# HDSC_HC32M120F6TB register map
Vendor: HDSC Co.,Ltd.; Series: ARMCM0P; File version: 1.0
CPU: CM0P r0p1, little endian, no MPU, no FPU, 4 interrupt priority bits
Registers are 32-bit, read-write, reset 0x0 unless marked. A register's access mark holds for its fields unless they carry their own. Offsets are from the block's base; [hi:lo] are bit positions; {n}, {i} and the like mark numbered series; 'fields as' and 'values as' point back to an identical list.

## CRC
Base 0x40015400
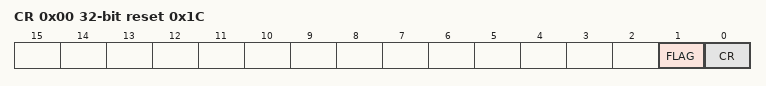
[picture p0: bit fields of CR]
0x00 CR reset 0x1C
  [1] FLAG, [0] CR
0x04 RESLT reset 0x7800
{0x80+4i} DAT{i} (i=0..31)

## CTC
Base 0x40000000
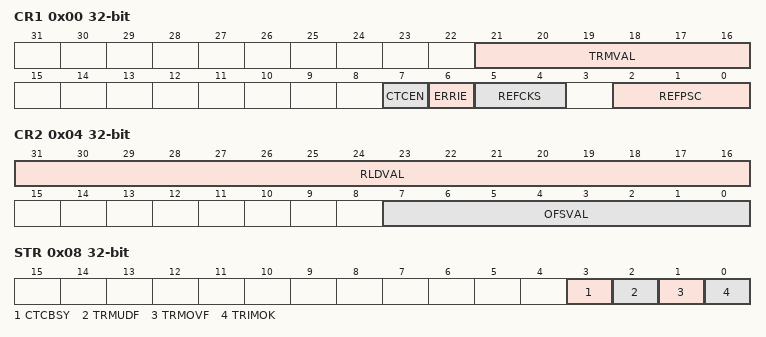
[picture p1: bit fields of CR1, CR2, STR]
0x00 CR1
  [21:16] TRMVAL, [7] CTCEN, [6] ERRIE, [5:4] REFCKS, [2:0] REFPSC
0x04 CR2
  [31:16] RLDVAL, [7:0] OFSVAL
0x08 STR ro
  [3] CTCBSY, [2] TRMUDF, [1] TRMOVF, [0] TRIMOK

## DBGC
Base 0x40015000
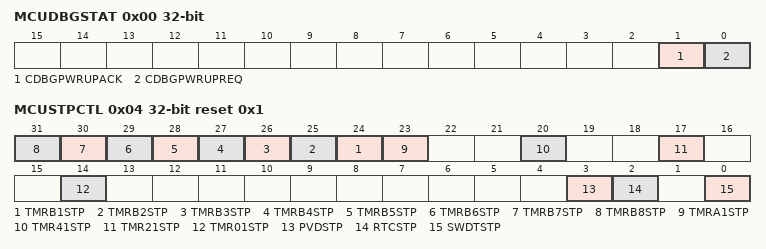
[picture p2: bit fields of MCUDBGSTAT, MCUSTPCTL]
0x00 MCUDBGSTAT
  [1] CDBGPWRUPACK, [0] CDBGPWRUPREQ
0x04 MCUSTPCTL reset 0x1
  [n+23] TMRB{n}STP (n=1..8), [23] TMRA1STP, [20] TMR41STP, [17] TMR21STP, [14] TMR01STP, [3] PVDSTP, [2] RTCSTP, [0] SWDTSTP

## DBGC_T
Base 0xE0042000
{0x0+4i} AUTHID{i} (i=0..2)
0x0C RESV0
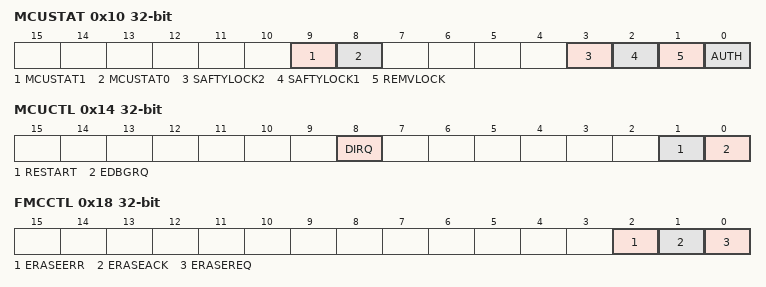
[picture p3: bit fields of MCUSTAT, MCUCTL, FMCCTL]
0x10 MCUSTAT
  [9] MCUSTAT1, [8] MCUSTAT0, [3] SAFTYLOCK2, [2] SAFTYLOCK1, [1] REMVLOCK, [0] AUTH
0x14 MCUCTL
  [8] DIRQ, [1] RESTART, [0] EDBGRQ
0x18 FMCCTL
  [2] ERASEERR, [1] ERASEACK, [0] ERASEREQ

## DMA
Base 0x40013000
0x00 EN
  [0] EN
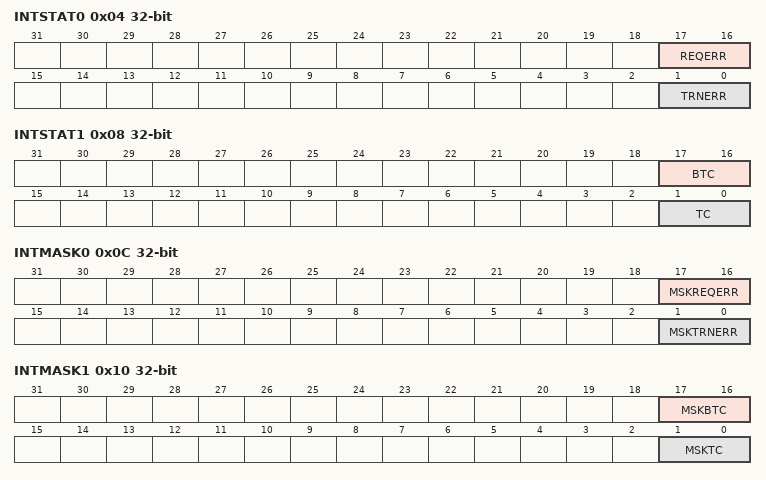
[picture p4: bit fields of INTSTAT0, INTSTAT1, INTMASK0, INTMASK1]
0x04 INTSTAT0 ro
  [17:16] REQERR, [1:0] TRNERR
0x08 INTSTAT1 ro
  [17:16] BTC, [1:0] TC
0x0C INTMASK0
  [17:16] MSKREQERR, [1:0] MSKTRNERR
0x10 INTMASK1
  [17:16] MSKBTC, [1:0] MSKTC
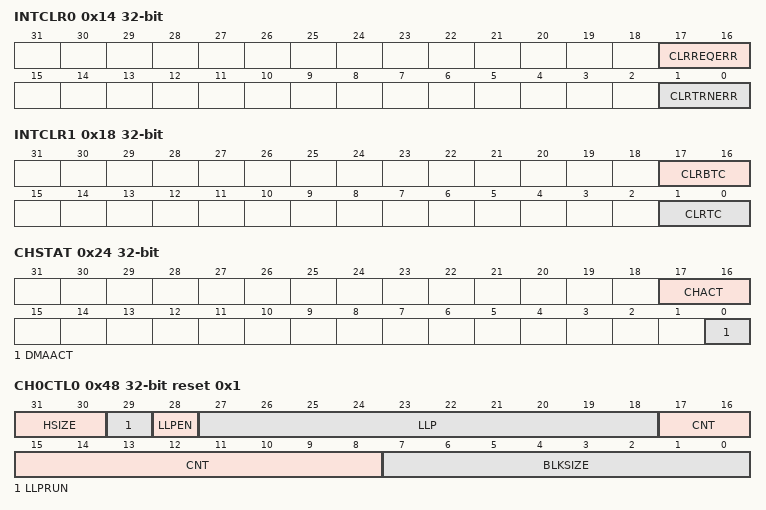
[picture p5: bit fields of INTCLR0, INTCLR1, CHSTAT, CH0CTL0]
0x14 INTCLR0 wo
  [17:16] CLRREQERR, [1:0] CLRTRNERR
0x18 INTCLR1 wo
  [17:16] CLRBTC, [1:0] CLRTC
0x1C CHEN
  [1:0] CHEN
0x24 CHSTAT ro
  [17:16] CHACT, [0] DMAACT
0x3C CHENCLR
  [1:0] CHENCLR
0x40 SAR0
0x44 DAR0
0x48 CH0CTL0 reset 0x1
  [31:30] HSIZE, [29] LLPRUN, [28] LLPEN, [27:18] LLP, [17:8] CNT, [7:0] BLKSIZE
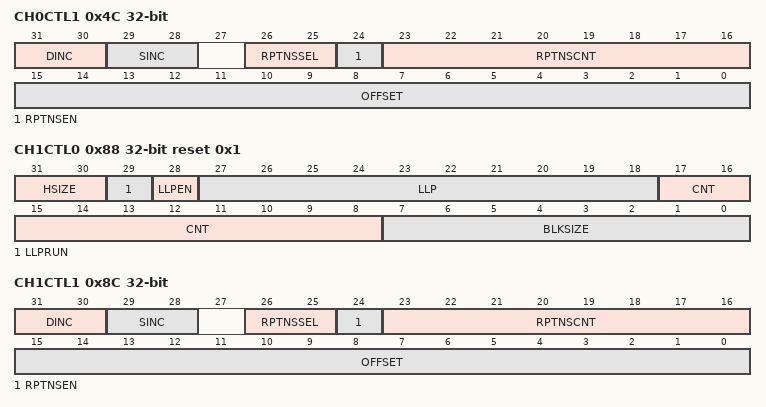
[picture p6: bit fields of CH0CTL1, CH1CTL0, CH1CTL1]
0x4C CH0CTL1
  [31:30] DINC, [29:28] SINC, [26:25] RPTNSSEL, [24] RPTNSEN, [23:16] RPTNSCNT, [15:0] OFFSET
0x80 SAR1
0x84 DAR1
0x88 CH1CTL0 reset 0x1
  fields as CH0CTL0
0x8C CH1CTL1
  fields as CH0CTL1

## EFM
Base 0x40000800
0x00 FAPRT
  [15:0] FAPRT
0x04 FSTP
  [0] FSTP
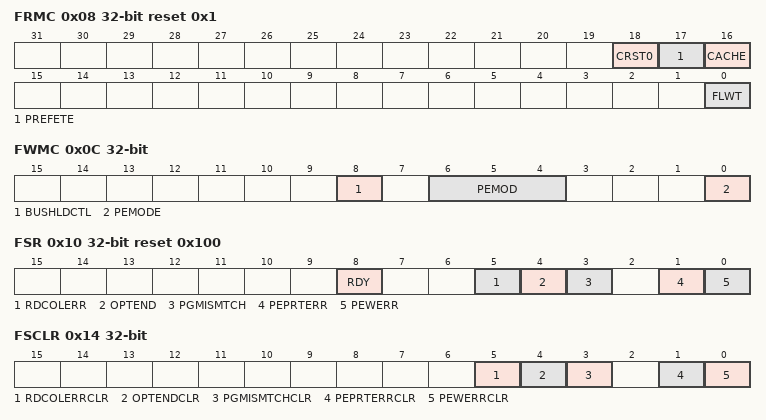
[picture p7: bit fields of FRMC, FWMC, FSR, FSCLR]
0x08 FRMC reset 0x1
  [18] CRST0, [17] PREFETE, [16] CACHE, [0] FLWT
0x0C FWMC
  [8] BUSHLDCTL, [6:4] PEMOD, [0] PEMODE
0x10 FSR ro reset 0x100
  [8] RDY, [5] RDCOLERR, [4] OPTEND, [3] PGMISMTCH, [1] PEPRTERR, [0] PEWERR
0x14 FSCLR
  [5] RDCOLERRCLR, [4] OPTENDCLR, [3] PGMISMTCHCLR, [1] PEPRTERRCLR, [0] PEWERRCLR
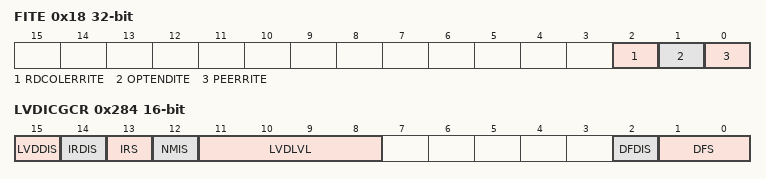
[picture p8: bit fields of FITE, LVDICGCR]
0x18 FITE
  [2] RDCOLERRITE, [1] OPTENDITE, [0] PEERRITE
0x20 FPMTSW
  [14:0] FPMTSW
0x24 FPMTEW
  [14:0] FPMTEW
{0x50+4i} UQID{i} ro (i=0..2)
0x282 HRCCFGR 8-bit
  [3:0] HRCFREQS
0x284 LVDICGCR 16-bit reset not defined
  [15] LVDDIS, [14] IRDIS, [13] IRS, [12] NMIS, [11:8] LVDLVL, [2] DFDIS, [1:0] DFS

## EMB
Base 0x40006C00
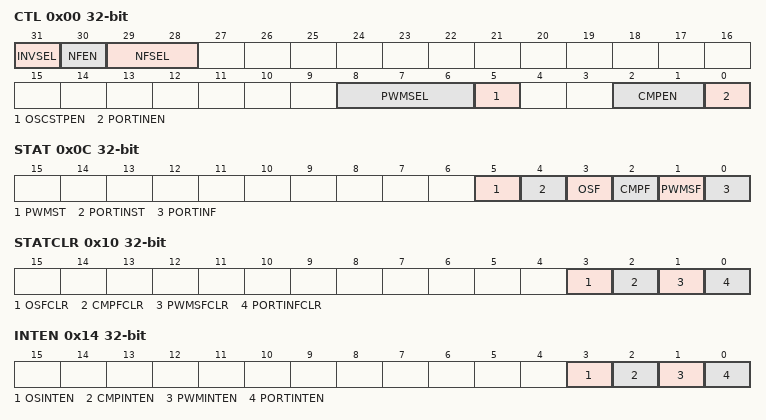
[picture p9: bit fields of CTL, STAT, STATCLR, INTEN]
0x00 CTL
  [31] INVSEL, [30] NFEN, [29:28] NFSEL, [8:6] PWMSEL, [5] OSCSTPEN, [2:1] CMPEN, [0] PORTINEN
0x04 PWMLV
  [2:0] PWMLV
0x08 SOE
  [0] SOE
0x0C STAT ro
  [5] PWMST, [4] PORTINST, [3] OSF, [2] CMPF, [1] PWMSF, [0] PORTINF
0x10 STATCLR wo
  [3] OSFCLR, [2] CMPFCLR, [1] PWMSFCLR, [0] PORTINFCLR
0x14 INTEN
  [3] OSINTEN, [2] CMPINTEN, [1] PWMINTEN, [0] PORTINTEN

## I2C
Base 0x40004800
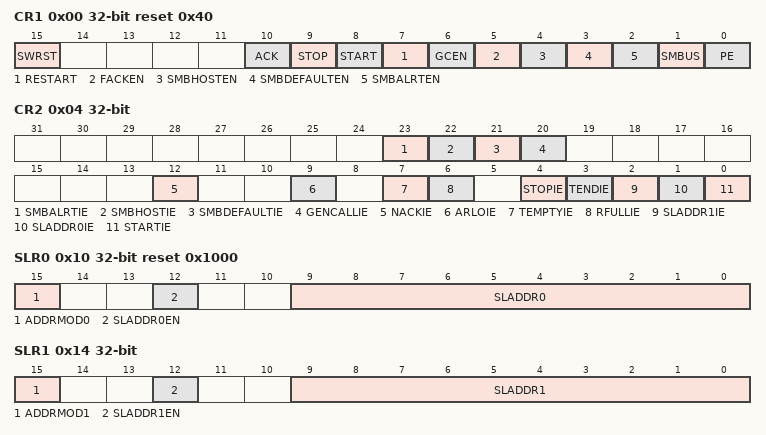
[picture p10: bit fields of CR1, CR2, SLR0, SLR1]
0x00 CR1 reset 0x40
  [15] SWRST, [10] ACK, [9] STOP, [8] START, [7] RESTART, [6] GCEN, [5] FACKEN, [4] SMBHOSTEN, [3] SMBDEFAULTEN, [2] SMBALRTEN, [1] SMBUS, [0] PE
0x04 CR2
  [23] SMBALRTIE, [22] SMBHOSTIE, [21] SMBDEFAULTIE, [20] GENCALLIE, [12] NACKIE, [9] ARLOIE, [7] TEMPTYIE, [6] RFULLIE, [4] STOPIE, [3] TENDIE, [2] SLADDR1IE, [1] SLADDR0IE, [0] STARTIE
0x10 SLR0 reset 0x1000
  [15] ADDRMOD0, [12] SLADDR0EN, [9:0] SLADDR0
0x14 SLR1
  [15] ADDRMOD1, [12] SLADDR1EN, [9:0] SLADDR1
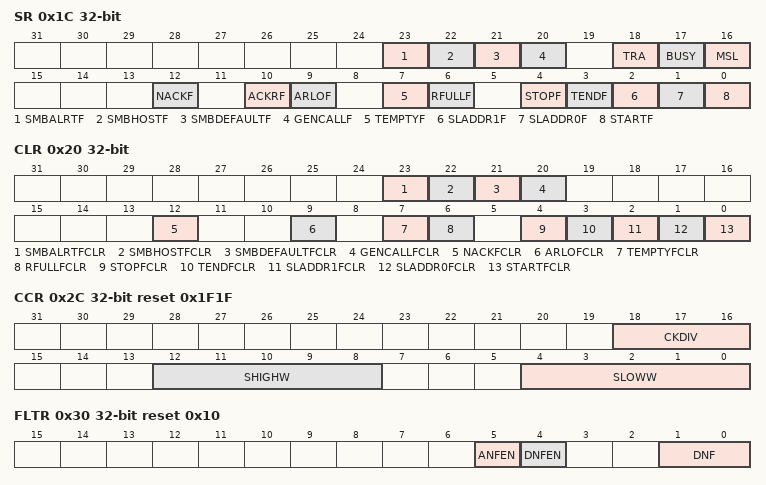
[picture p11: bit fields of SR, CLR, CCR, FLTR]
0x1C SR ro
  [23] SMBALRTF, [22] SMBHOSTF, [21] SMBDEFAULTF, [20] GENCALLF, [18] TRA rw, [17] BUSY, [16] MSL rw, [12] NACKF, [10] ACKRF, [9] ARLOF, [7] TEMPTYF, [6] RFULLF, [4] STOPF, [3] TENDF, [2] SLADDR1F, [1] SLADDR0F, [0] STARTF
0x20 CLR wo
  [23] SMBALRTFCLR, [22] SMBHOSTFCLR, [21] SMBDEFAULTFCLR, [20] GENCALLFCLR, [12] NACKFCLR, [9] ARLOFCLR, [7] TEMPTYFCLR, [6] RFULLFCLR, [4] STOPFCLR, [3] TENDFCLR, [2] SLADDR1FCLR, [1] SLADDR0FCLR, [0] STARTFCLR
0x24 DTR 8-bit reset 0xFF
  [7:0] DT
0x28 DRR 8-bit
  [7:0] DR
0x2C CCR reset 0x1F1F
  [18:16] CKDIV, [12:8] SHIGHW, [4:0] SLOWW
0x30 FLTR reset 0x10
  [5] ANFEN, [4] DNFEN, [1:0] DNF
